# ATmega128RFA1 register map
Vendor: Atmel; File version: 1.0
CPU: other r0p0, little endian, no MPU, no FPU, 4 interrupt priority bits
Registers are 8-bit, read-write, reset 0x0 unless marked. A register's access mark holds for its fields unless they carry their own. Offsets are from the block's base; [hi:lo] are bit positions.

## SPI — Serial Peripheral Interface
Base 0x0080004C
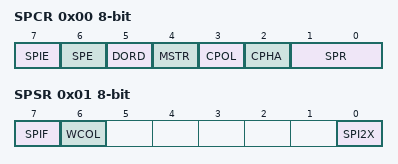
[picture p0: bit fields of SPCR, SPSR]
0x00 SPCR — SPI Control Register
  [7] SPIE — SPI Interrupt Enable
  [6] SPE — SPI Enable
  [5] DORD — Data Order
  [4] MSTR — Master/Slave Select
  [3] CPOL — Clock polarity
    0=RISING_LEADING_EDGE_FALLING_TRAILING_EDGE; 1=FALLING_LEADING_EGDE_RISING_TRAILING_EDGE (Falling (Leading Edge), Rising (Trailing Edge))
  [2] CPHA — Clock Phase
    0=SAMPLE_LEADING_EDGE_SETUP_TRAILING_EDGE; 1=SETUP_LEADING_EDGE_SAMPLE_TRAILING_EDGE
  [1:0] SPR — SPI Clock Rate Select 1 and 0
    0=FOSC_4; 1=FOSC_16; 3=FOSC_128
0x01 SPSR — SPI Status Register (read-only for debugger)
  [7] SPIF — SPI Interrupt Flag
  [6] WCOL — Write Collision Flag
  [0] SPI2X — Double SPI Speed Bit
0x02 SPDR — SPI Data Register (write-only for debugger)

## SYMCNT — MAC Symbol Counter
Base 0x008000DC
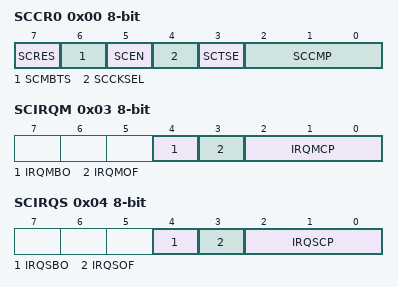
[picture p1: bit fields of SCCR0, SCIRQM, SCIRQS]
0x00 SCCR0 — Symbol Counter Control Register 0
  [7] SCRES — Symbol Counter Synchronization
  [6] SCMBTS — Manual Beacon Timestamp
  [5] SCEN — Symbol Counter enable
  [4] SCCKSEL — Symbol Counter Clock Source select
  [3] SCTSE — Symbol Counter Automatic Timestamping enable
  [2:0] SCCMP — Symbol Counter Compare Unit 3 Mode select
0x01 SCCR1 — Symbol Counter Control Register 1
  [0] SCENBO — Backoff Slot Counter enable
0x02 SCSR — Symbol Counter Status Register (read-only for debugger)
  [0] SCBSY — Symbol Counter busy
0x03 SCIRQM — Symbol Counter Interrupt Mask Register
  [4] IRQMBO — Backoff Slot Counter IRQ enable
  [3] IRQMOF — Symbol Counter Overflow IRQ enable
  [2:0] IRQMCP — Symbol Counter Compare Match 3 IRQ enable
0x04 SCIRQS — Symbol Counter Interrupt Status Register
  [4] IRQSBO — Backoff Slot Counter IRQ
  [3] IRQSOF — Symbol Counter Overflow IRQ
  [2:0] IRQSCP — Compare Unit 3 Compare Match IRQ
0x05 SCCNTLL — Symbol Counter Register LL-Byte
0x06 SCCNTLH — Symbol Counter Register LH-Byte
0x07 SCCNTHL — Symbol Counter Register HL-Byte
0x08 SCCNTHH — Symbol Counter Register HH-Byte
0x09 SCBTSRLL — Symbol Counter Beacon Timestamp Register LL-Byte
0x0A SCBTSRLH — Symbol Counter Beacon Timestamp Register LH-Byte
0x0B SCBTSRHL — Symbol Counter Beacon Timestamp Register HL-Byte
0x0C SCBTSRHH — Symbol Counter Beacon Timestamp Register HH-Byte
0x0D SCTSRLL — Symbol Counter Frame Timestamp Register LL-Byte (read-only for debugger)
  [7:0] SCTSRLL — Symbol Counter Frame Timestamp Register LL-Byte
0x0E SCTSRLH — Symbol Counter Frame Timestamp Register LH-Byte (read-only for debugger)
  [7:0] SCTSRLH — Symbol Counter Frame Timestamp Register LH-Byte
0x0F SCTSRHL — Symbol Counter Frame Timestamp Register HL-Byte (read-only for debugger)
  [7:0] SCTSRHL — Symbol Counter Frame Timestamp Register HL-Byte
0x10 SCTSRHH — Symbol Counter Frame Timestamp Register HH-Byte (read-only for debugger)
  [7:0] SCTSRHH — Symbol Counter Frame Timestamp Register HH-Byte
0x11 SCOCR3LL — Symbol Counter Output Compare Register 3 LL-Byte
0x12 SCOCR3LH — Symbol Counter Output Compare Register 3 LH-Byte
0x13 SCOCR3HL — Symbol Counter Output Compare Register 3 HL-Byte
0x14 SCOCR3HH — Symbol Counter Output Compare Register 3 HH-Byte
0x15 SCOCR2LL — Symbol Counter Output Compare Register 2 LL-Byte
0x16 SCOCR2LH — Symbol Counter Output Compare Register 2 LH-Byte
0x17 SCOCR2HL — Symbol Counter Output Compare Register 2 HL-Byte
0x18 SCOCR2HH — Symbol Counter Output Compare Register 2 HH-Byte
0x19 SCOCR1LL — Symbol Counter Output Compare Register 1 LL-Byte
0x1A SCOCR1LH — Symbol Counter Output Compare Register 1 LH-Byte
0x1B SCOCR1HL — Symbol Counter Output Compare Register 1 HL-Byte
0x1C SCOCR1HH — Symbol Counter Output Compare Register 1 HH-Byte

## TC0 — Timer/Counter, 8-bit
Base 0x00800035
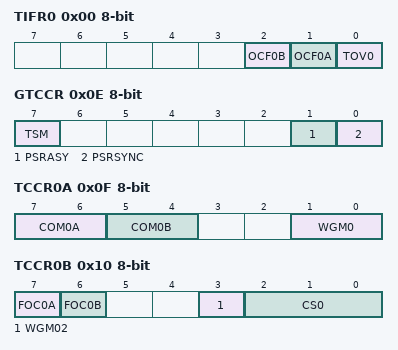
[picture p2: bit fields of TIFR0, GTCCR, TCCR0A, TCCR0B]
0x00 TIFR0 — Timer/Counter0 Interrupt Flag Register (read-only for debugger)
  [2] OCF0B — Timer/Counter0 Output Compare B Match Flag
  [1] OCF0A — Timer/Counter0 Output Compare A Match Flag
  [0] TOV0 — Timer/Counter0 Overflow Flag
0x0E GTCCR — General Timer/Counter Control Register
  [7] TSM — Timer/Counter Synchronization Mode
  [1] PSRASY — Prescaler Reset Timer/Counter2
  [0] PSRSYNC — Prescaler Reset for Synchronous Timer/Counters
0x0F TCCR0A — Timer/Counter0 Control Register A
  [7:6] COM0A — Compare Match Output A Mode
    0=NORMAL_PORT_OPERATION_OC0A_DISCONNECTED; 1=TOGGLE_OC0A_ON_COMPARE_MATCH; 2=CLEAR_OC0A_ON_COMPARE_MATCH; 3=SET_OC0A_ON_COMPARE_MATCH
  [5:4] COM0B — Compare Match Output B Mode
    0=NORMAL_PORT_OPERATION_OC0B_DISCONNECTED; 1=TOGGLE_OC0B_ON_COMPARE_MATCH; 2=CLEAR_OC0B_ON_COMPARE_MATCH; 3=SET_OC0B_ON_COMPARE_MATCH
  [1:0] WGM0 — Waveform Generation Mode
    0=NORMAL_MODE_OF_OPERATION; 1=PWM_PHASE_CORRECT_TOP_0XFF; 2=CTC_TOP_OCRA; 3=FAST_PWM_TOP_0XFF
0x10 TCCR0B — Timer/Counter0 Control Register B
  [7] FOC0A — Force Output Compare A
  [6] FOC0B — Force Output Compare B
  [3] WGM02
  [2:0] CS0 — Clock Select
    0=NO_CLOCK_SOURCE_TIMER_COUNTER0_STOPPED; 1=CLK_IO_1_NO_PRESCALING; 2=CLK_IO_8_FROM_PRESCALER; 3=CLK_IO_64_FROM_PRESCALER; 4=CLK_IO_256_FROM_PRESCALER; 5=CLK_IO_1024_FROM_PRESCALER; 6=EXTERNAL_CLOCK_SOURCE_ON_T0_PIN_CLOCK_ON_FALLING_EDGE; 7=EXTERNAL_CLOCK_SOURCE_ON_T0_PIN_CLOCK_ON_RISING_EDGE
0x11 TCNT0 — Timer/Counter0 Register
0x12 OCR0A — Timer/Counter0 Output Compare Register
0x13 OCR0B — Timer/Counter0 Output Compare Register B
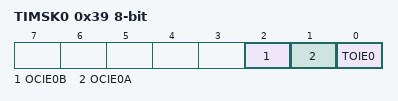
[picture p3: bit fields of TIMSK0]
0x39 TIMSK0 — Timer/Counter0 Interrupt Mask Register
  [2] OCIE0B — Timer/Counter0 Output Compare Match B Interrupt Enable
  [1] OCIE0A — Timer/Counter0 Output Compare Match A Interrupt Enable
  [0] TOIE0 — Timer/Counter0 Overflow Interrupt Enable
